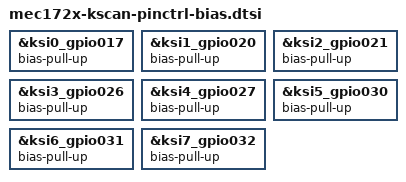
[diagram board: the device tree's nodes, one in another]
/*
 * Copyright (c) 2024, Intel Corporation.
 *
 * SPDX-License-Identifier: Apache-2.0
 */

&ksi0_gpio017 {
	bias-pull-up;
};

&ksi1_gpio020 {
	bias-pull-up;
};

&ksi2_gpio021 {
	bias-pull-up;
};

&ksi3_gpio026 {
	bias-pull-up;
};

&ksi4_gpio027 {
	bias-pull-up;
};

&ksi5_gpio030 {
	bias-pull-up;
};

&ksi6_gpio031 {
	bias-pull-up;
};

&ksi7_gpio032 {
	bias-pull-up;
};
